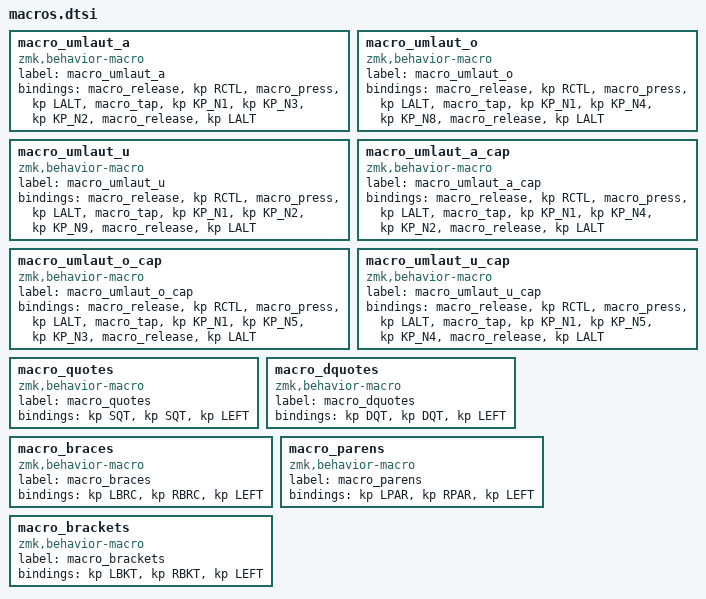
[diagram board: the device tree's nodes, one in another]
macro_umlaut_a: macro_umlaut_a{
compatible = "zmk,behavior-macro";
label = "macro_umlaut_a";
#binding-cells = <0>;
bindings
      = <&macro_release &kp RCTL>
      , <&macro_press &kp LALT>
      , <&macro_tap &kp KP_N1 &kp KP_N3 &kp KP_N2>
      , <&macro_release &kp LALT>;
};
macro_umlaut_o: macro_umlaut_o{
compatible = "zmk,behavior-macro";
label = "macro_umlaut_o";
#binding-cells = <0>;
bindings
      = <&macro_release &kp RCTL>
      , <&macro_press &kp LALT>
      , <&macro_tap &kp KP_N1 &kp KP_N4 &kp KP_N8>
      , <&macro_release &kp LALT>;
};
macro_umlaut_u: macro_umlaut_u{
compatible = "zmk,behavior-macro";
label = "macro_umlaut_u";
#binding-cells = <0>;
bindings
      = <&macro_release &kp RCTL>
      , <&macro_press &kp LALT>
      , <&macro_tap &kp KP_N1 &kp KP_N2 &kp KP_N9>
      , <&macro_release &kp LALT>;
};
macro_umlaut_a_cap: macro_umlaut_a_cap{
compatible = "zmk,behavior-macro";
label = "macro_umlaut_a_cap";
#binding-cells = <0>;
bindings
      = <&macro_release &kp RCTL>
      , <&macro_press &kp LALT>
      , <&macro_tap &kp KP_N1 &kp KP_N4 &kp KP_N2>
      , <&macro_release &kp LALT>;
};
macro_umlaut_o_cap: macro_umlaut_o_cap{
compatible = "zmk,behavior-macro";
label = "macro_umlaut_o_cap";
#binding-cells = <0>;
bindings
      = <&macro_release &kp RCTL>
      , <&macro_press &kp LALT>
      , <&macro_tap &kp KP_N1 &kp KP_N5 &kp KP_N3>
      , <&macro_release &kp LALT>;
};
macro_umlaut_u_cap: macro_umlaut_u_cap{
compatible = "zmk,behavior-macro";
label = "macro_umlaut_u_cap";
#binding-cells = <0>;
bindings
      = <&macro_release &kp RCTL>
      , <&macro_press &kp LALT>
      , <&macro_tap &kp KP_N1 &kp KP_N5 &kp KP_N4>
      , <&macro_release &kp LALT>;
};
macro_quotes: macro_quotes{
compatible = "zmk,behavior-macro";
label = "macro_quotes";
#binding-cells = <0>;
bindings = <&kp SQT>, <&kp SQT>, <&kp LEFT>;
};
macro_dquotes: macro_dquotes{
compatible = "zmk,behavior-macro";
label = "macro_dquotes";
#binding-cells = <0>;
bindings = <&kp DQT>, <&kp DQT>, <&kp LEFT>;
};
macro_braces: macro_braces{
compatible = "zmk,behavior-macro";
label = "macro_braces";
#binding-cells = <0>;
bindings = <&kp LBRC>, <&kp RBRC>, <&kp LEFT>;
};
macro_parens: macro_parens{
compatible = "zmk,behavior-macro";
label = "macro_parens";
#binding-cells = <0>;
bindings = <&kp LPAR>, <&kp RPAR>, <&kp LEFT>;
};
macro_brackets: macro_brackets{
compatible = "zmk,behavior-macro";
label = "macro_brackets";
#binding-cells = <0>;
bindings = <&kp LBKT>, <&kp RBKT>, <&kp LEFT>;
};
